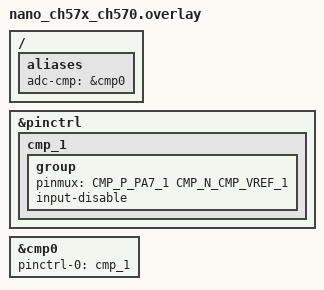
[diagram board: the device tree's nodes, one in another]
/*
 * SPDX-FileCopyrightText: 2026 SMILE (smile.eu)
 *
 * SPDX-License-Identifier: Apache-2.0
 */

#include <zephyr/dt-bindings/pinctrl/ch570-pinctrl.h>

/ {
	aliases {
		adc-cmp = &cmp0;
	};
};

&pinctrl {
	cmp_1: cmp_1 {
		group {
			pinmux = <CMP_P_PA7_1 CMP_N_CMP_VREF_1>;
			input-disable;
		};
	};
};

&cmp0 {
	status = "okay";
	pinctrl-0 = <&cmp_1>;
	pinctrl-names = "default";
};
